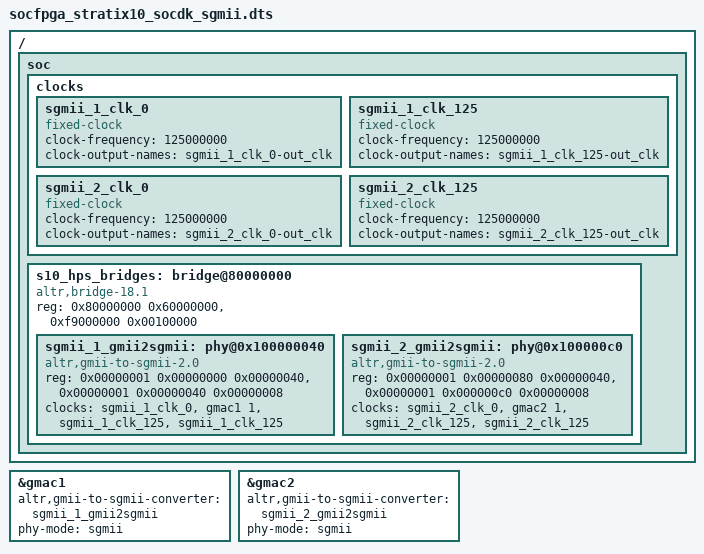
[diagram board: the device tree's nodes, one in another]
// SPDX-License-Identifier: GPL-2.0-only
/*
 * Copyright Altera Corporation (C) 2021. All rights reserved.
 */

#define DISABLE_QSE
#include "socfpga_stratix10_socdk.dts"

/{
	soc {
		clocks {
			sgmii_1_clk_0: sgmii_1_clk_0 {
                                compatible = "fixed-clock";
                                #clock-cells = <0>;
                                clock-frequency = <125000000>;  /* 125.00 MHz */
                                clock-output-names = "sgmii_1_clk_0-out_clk";
                        }; //end sgmii_1_clk_0 (sgmii_1_clk_0)

                        sgmii_1_clk_125: sgmii_1_clk_125 {
                                compatible = "fixed-clock";
                                #clock-cells = <0>;
                                clock-frequency = <125000000>;  /* 125.00 MHz */
                                clock-output-names = "sgmii_1_clk_125-out_clk";
                        }; //end sgmii_1_clk_125 (sgmii_1_clk_125)

                        sgmii_2_clk_0: sgmii_2_clk_0 {
                                compatible = "fixed-clock";
                                #clock-cells = <0>;
                                clock-frequency = <125000000>;  /* 125.00 MHz */
                                clock-output-names = "sgmii_2_clk_0-out_clk";
                        }; //end sgmii_2_clk_0 (sgmii_2_clk_0)

                        sgmii_2_clk_125: sgmii_2_clk_125 {
                                compatible = "fixed-clock";
                                #clock-cells = <0>;
                                clock-frequency = <125000000>;  /* 125.00 MHz */
                                clock-output-names = "sgmii_2_clk_125-out_clk";
                        }; //end sgmii_2_clk_125 (sgmii_2_clk_125)
		};

		s10_hps_bridges: bridge@80000000 {
                        compatible = "altr,bridge-18.1", "simple-bus";
                        reg = <0x80000000 0x60000000>,
                                <0xf9000000 0x00100000>;
                        reg-names = "axi_h2f", "axi_h2f_lw";
                        #address-cells = <2>;
                        #size-cells = <1>;
                        ranges = <0x00000000 0x00000000 0x80000000 0x00040000>,
                                <0x00000001 0x00000000 0xf9010000 0x00000040>,
                                <0x00000001 0x00000040 0xf9010040 0x00000008>,
                                <0x00000001 0x0000080 0xf9010080 0x00000040>,
                                <0x00000001 0x00000c0 0xf90100c0 0x00000008>;

                        sgmii_1_gmii2sgmii: phy@0x100000040 {
                                compatible = "altr,gmii-to-sgmii-2.0";
                                reg = <0x00000001 0x00000000 0x00000040>,
                                        <0x00000001 0x00000040 0x00000008>;
                                reg-names = "eth_tse_control_port", "gmii_to_sgmii_adapter_avalon_slave";
                                clocks = <&sgmii_1_clk_0 &gmac1 1 &sgmii_1_clk_125 &sgmii_1_clk_125>;
                                clock-names = "clock_in", "emac_gtx_clk", "tse_pcs_ref_clk_clock_connection", "tse_rx_cdr_refclk";
                        }; //end phy@0x100000040 (sgmii_1_gmii2sgmii)

                        sgmii_2_gmii2sgmii: phy@0x100000c0 {
                                compatible = "altr,gmii-to-sgmii-2.0";
                                reg = <0x00000001 0x00000080 0x00000040>,
                                        <0x00000001 0x000000c0 0x00000008>;
                                reg-names = "eth_tse_control_port", "gmii_to_sgmii_adapter_avalon_slave";
                                clocks = <&sgmii_2_clk_0 &gmac2 1 &sgmii_2_clk_125 &sgmii_2_clk_125>;
                                clock-names = "clock_in", "emac_gtx_clk", "tse_pcs_ref_clk_clock_connection", "tse_rx_cdr_refclk";
                        }; //end phy@0x1000000c0 (sgmii_2_gmii2sgmii)
                };

	};
};

&gmac1 {
        altr,gmii-to-sgmii-converter = <&sgmii_1_gmii2sgmii>;
	#clock-cells = <1>;
        phy-mode = "sgmii";
        status = "okay";
};

&gmac2 {
        altr,gmii-to-sgmii-converter = <&sgmii_2_gmii2sgmii>;
	#clock-cells = <1>;
        phy-mode = "sgmii";
        status = "okay";
};
